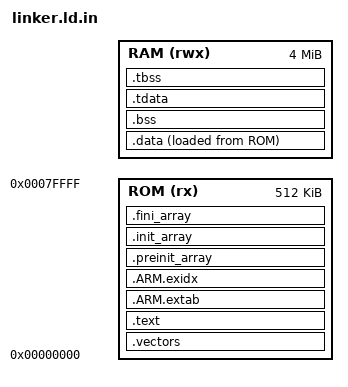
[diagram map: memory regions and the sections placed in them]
/* SPDX-License-Identifier: MIT */
ENTRY(Reset_Handler)
MEMORY {
    ROM (rx) : ORIGIN = 0, LENGTH = 512K
    RAM (rwx) : ORIGIN = @ram_address@, LENGTH = 4M
}
_estack = ORIGIN(RAM) + LENGTH(RAM);
_sstack = _estack - 16384;
SECTIONS {
    .vectors : { KEEP(*(.vectors)) } > ROM
    .text : { *(.text*) *(.rodata*) KEEP(*(.init)) KEEP(*(.fini)) } > ROM
    .ARM.extab : { *(.ARM.extab*) } > ROM
    .ARM.exidx : { __exidx_start = .; *(.ARM.exidx*) __exidx_end = .; } > ROM
    .preinit_array : { PROVIDE_HIDDEN(__preinit_array_start = .); KEEP(*(.preinit_array*)) PROVIDE_HIDDEN(__preinit_array_end = .); } > ROM
    .init_array : { PROVIDE_HIDDEN(__init_array_start = .); KEEP(*(SORT(.init_array.*))) KEEP(*(.init_array)) PROVIDE_HIDDEN(__init_array_end = .); } > ROM
    .fini_array : { PROVIDE_HIDDEN(__fini_array_start = .); KEEP(*(SORT(.fini_array.*))) KEEP(*(.fini_array)) PROVIDE_HIDDEN(__fini_array_end = .); } > ROM
    .data : ALIGN(8) { _sdata = .; *(.data*) _edata = .; } > RAM AT> ROM
    _sidata = LOADADDR(.data);
    .bss (NOLOAD) : ALIGN(8) { _sbss = .; *(.bss*) *(COMMON) . = ALIGN(8); _ebss = .; } > RAM
    .tdata : { *(.tdata*) } > RAM
    .tbss : { *(.tbss*) } > RAM
    ASSERT(_ebss <= _sstack, "Runtime overlaps MSP stack")
    ASSERT(SIZEOF(.tdata) == 0 && SIZEOF(.tbss) == 0, "Native ELF TLS is unsupported")
}
